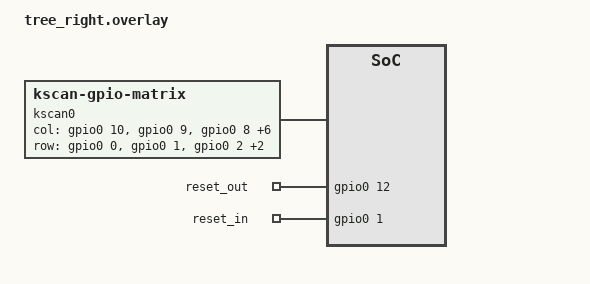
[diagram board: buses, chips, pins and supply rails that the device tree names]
/*
 * Copyright (c) 2022 The ZMK Contributors
 *
 * SPDX-License-Identifier: MIT
 */

&default_transform {
    col-offset = <7>;
};

/ {
	chosen {
		zmk,kscan = &kscan0;
	};

	kscan0: kscan {
		compatible = "zmk,kscan-gpio-matrix";
    diode-direction = "col2row";
		col-gpios
			= <&gpio0 10 (GPIO_ACTIVE_HIGH)>
			, <&gpio0 9 (GPIO_ACTIVE_HIGH)>
			, <&gpio0 8 (GPIO_ACTIVE_HIGH)>
			, <&gpio0 7 (GPIO_ACTIVE_HIGH)>
			, <&gpio0 6 (GPIO_ACTIVE_HIGH)>
			, <&gpio0 5 (GPIO_ACTIVE_HIGH)>
			, <&gpio0 11 (GPIO_ACTIVE_HIGH)>
			, <&gpio0 12 (GPIO_ACTIVE_HIGH)>
			, <&gpio0 13 (GPIO_ACTIVE_HIGH)>
			;
		row-gpios
			= <&gpio0 0 (GPIO_ACTIVE_HIGH | GPIO_PULL_DOWN)>
			, <&gpio0 1 (GPIO_ACTIVE_HIGH | GPIO_PULL_DOWN)>
			, <&gpio0 2 (GPIO_ACTIVE_HIGH | GPIO_PULL_DOWN)>
			, <&gpio0 3 (GPIO_ACTIVE_HIGH | GPIO_PULL_DOWN)>
			, <&gpio0 4 (GPIO_ACTIVE_HIGH | GPIO_PULL_DOWN)>
			;
	};

	leds {
		resetout: reset_out {
			gpios = <&gpio0 12 (GPIO_ACTIVE_HIGH)>;
			label = "reset_out";
		};
		resetin: reset_in {
			gpios = <&gpio0 1 (GPIO_ACTIVE_HIGH | GPIO_PULL_DOWN)>;
			label = "reset_in";
		};
	};

/** # Uncomment to enable encoder, but doesn't work over BLE */
/*
  right_encoder: encoder_right {
      compatible = "alps,ec11";
      label = "RIGHT_ENCODER";
      a-gpios = <&gpio0 25 (GPIO_ACTIVE_HIGH | GPIO_PULL_UP)>;
      b-gpios = <&gpio0 26 (GPIO_ACTIVE_HIGH | GPIO_PULL_UP)>;
      resolution = <4>;
      status = "okay";
  };

  sensors {
      compatible = "zmk,keymap-sensors";
      sensors = <&right_encoder>;
  };
*/
};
